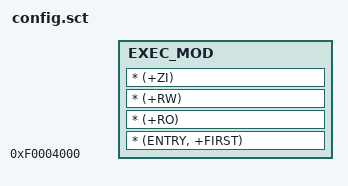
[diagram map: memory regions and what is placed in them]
;/*
;********************************************************************************************************
;*											        ePDK
;*						            the Easy Portable/Player Develop Kits
;*									           standby sample
;*
;*						        (c) Copyright 2006-2010, kevin.z China
;*											All	Rights Reserved
;*
;* File    : scatter.sct
;* By      : kevin.z
;* Version : V1.00
;********************************************************************************************************
;*/


LO_FIRST 0xf0004000 0x4000
{
    EXEC_MOD  0xf0004000
    {
        * (ENTRY, +FIRST)
        * (+RO)
        * (+RW)
        * (+ZI)
	}
}
